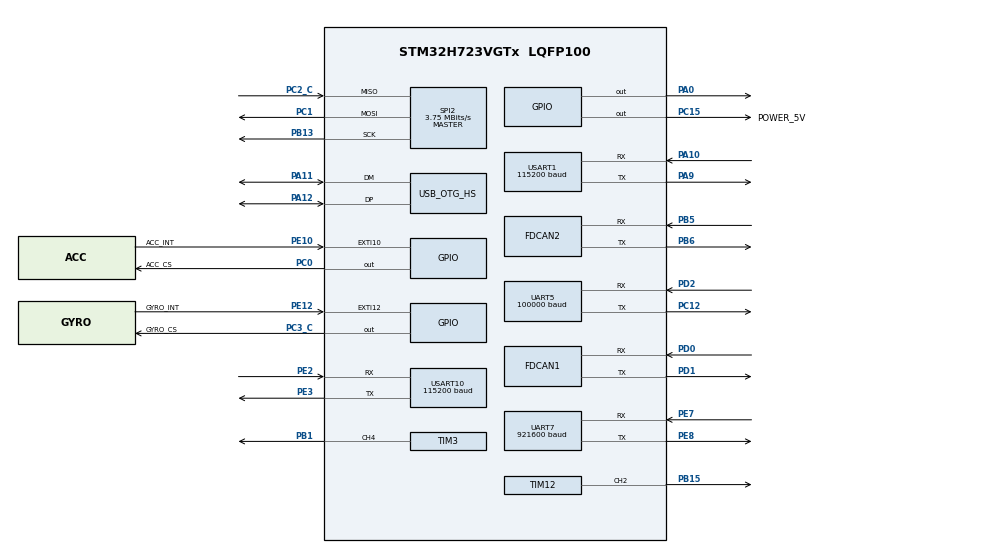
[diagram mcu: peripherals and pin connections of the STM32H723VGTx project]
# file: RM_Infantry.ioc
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CORTEX_M7.BaseAddress-Cortex_Memory_Protection_Unit_Region0_Settings=0x24000000
CORTEX_M7.CPU_DCache=Disabled
CORTEX_M7.CPU_ICache=Enabled
CORTEX_M7.Enable-Cortex_Memory_Protection_Unit_Region0_Settings=MPU_REGION_ENABLE
CORTEX_M7.IsBufferable-Cortex_Memory_Protection_Unit_Region0_Settings=MPU_ACCESS_BUFFERABLE
CORTEX_M7.IsCacheable-Cortex_Memory_Protection_Unit_Region0_Settings=MPU_ACCESS_CACHEABLE
CORTEX_M7.MPU_Control=MPU_HFNMI_PRIVDEF
CORTEX_M7.Size-Cortex_Memory_Protection_Unit_Region0_Settings=MPU_REGION_SIZE_512KB
CORTEX_M7.TypeExtField-Cortex_Memory_Protection_Unit_Region0_Settings=MPU_TEX_LEVEL1
CORTEX_M7.default_mode_Activation=1
Dma.Request0=SPI2_RX
Dma.Request1=SPI2_TX
Dma.Request2=UART5_RX
Dma.Request3=USART1_TX
Dma.Request4=UART7_RX
Dma.Request5=UART7_TX
Dma.Request6=USART10_RX
Dma.Request7=USART10_TX
Dma.Request8=USART1_RX
Dma.SPI2_RX.0.Direction=DMA_PERIPH_TO_MEMORY
Dma.SPI2_RX.0.EventEnable=DISABLE
Dma.SPI2_RX.0.FIFOMode=DMA_FIFOMODE_DISABLE
Dma.SPI2_RX.0.Instance=DMA1_Stream1
Dma.SPI2_RX.0.MemDataAlignment=DMA_MDATAALIGN_BYTE
Dma.SPI2_RX.0.MemInc=DMA_MINC_ENABLE
Dma.SPI2_RX.0.Mode=DMA_NORMAL
Dma.SPI2_RX.0.PeriphDataAlignment=DMA_PDATAALIGN_BYTE
Dma.SPI2_RX.0.PeriphInc=DMA_PINC_DISABLE
Dma.SPI2_RX.0.Polarity=HAL_DMAMUX_REQ_GEN_RISING
Dma.SPI2_RX.0.Priority=DMA_PRIORITY_HIGH
Dma.SPI2_RX.0.RequestNumber=1
Dma.SPI2_RX.0.SignalID=NONE
Dma.SPI2_RX.0.SyncEnable=DISABLE
Dma.SPI2_RX.0.SyncPolarity=HAL_DMAMUX_SYNC_NO_EVENT
Dma.SPI2_RX.0.SyncRequestNumber=1
Dma.SPI2_RX.0.SyncSignalID=NONE
Dma.SPI2_TX.1.Direction=DMA_MEMORY_TO_PERIPH
Dma.SPI2_TX.1.EventEnable=DISABLE
Dma.SPI2_TX.1.FIFOMode=DMA_FIFOMODE_DISABLE
Dma.SPI2_TX.1.Instance=DMA1_Stream2
Dma.SPI2_TX.1.MemDataAlignment=DMA_MDATAALIGN_BYTE
Dma.SPI2_TX.1.MemInc=DMA_MINC_ENABLE
Dma.SPI2_TX.1.Mode=DMA_NORMAL
Dma.SPI2_TX.1.PeriphDataAlignment=DMA_PDATAALIGN_BYTE
Dma.SPI2_TX.1.PeriphInc=DMA_PINC_DISABLE
Dma.SPI2_TX.1.Polarity=HAL_DMAMUX_REQ_GEN_RISING
Dma.SPI2_TX.1.Priority=DMA_PRIORITY_MEDIUM
Dma.SPI2_TX.1.RequestNumber=1
Dma.SPI2_TX.1.SignalID=NONE
Dma.SPI2_TX.1.SyncEnable=DISABLE
Dma.SPI2_TX.1.SyncPolarity=HAL_DMAMUX_SYNC_NO_EVENT
Dma.SPI2_TX.1.SyncRequestNumber=1
Dma.SPI2_TX.1.SyncSignalID=NONE
Dma.UART5_RX.2.Direction=DMA_PERIPH_TO_MEMORY
Dma.UART5_RX.2.EventEnable=DISABLE
Dma.UART5_RX.2.FIFOMode=DMA_FIFOMODE_DISABLE
Dma.UART5_RX.2.Instance=DMA1_Stream3
Dma.UART5_RX.2.MemDataAlignment=DMA_MDATAALIGN_BYTE
Dma.UART5_RX.2.MemInc=DMA_MINC_ENABLE
Dma.UART5_RX.2.Mode=DMA_NORMAL
Dma.UART5_RX.2.PeriphDataAlignment=DMA_PDATAALIGN_BYTE
Dma.UART5_RX.2.PeriphInc=DMA_PINC_DISABLE
Dma.UART5_RX.2.Polarity=HAL_DMAMUX_REQ_GEN_RISING
Dma.UART5_RX.2.Priority=DMA_PRIORITY_LOW
Dma.UART5_RX.2.RequestNumber=1
Dma.UART5_RX.2.SignalID=NONE
Dma.UART5_RX.2.SyncEnable=DISABLE
Dma.UART5_RX.2.SyncPolarity=HAL_DMAMUX_SYNC_NO_EVENT
Dma.UART5_RX.2.SyncRequestNumber=1
Dma.UART5_RX.2.SyncSignalID=NONE
Dma.UART7_RX.4.Direction=DMA_PERIPH_TO_MEMORY
Dma.UART7_RX.4.EventEnable=DISABLE
Dma.UART7_RX.4.FIFOMode=DMA_FIFOMODE_DISABLE
Dma.UART7_RX.4.Instance=DMA2_Stream1
Dma.UART7_RX.4.MemDataAlignment=DMA_MDATAALIGN_BYTE
Dma.UART7_RX.4.MemInc=DMA_MINC_ENABLE
Dma.UART7_RX.4.Mode=DMA_NORMAL
Dma.UART7_RX.4.PeriphDataAlignment=DMA_PDATAALIGN_BYTE
Dma.UART7_RX.4.PeriphInc=DMA_PINC_DISABLE
Dma.UART7_RX.4.Polarity=HAL_DMAMUX_REQ_GEN_RISING
Dma.UART7_RX.4.Priority=DMA_PRIORITY_HIGH
Dma.UART7_RX.4.RequestNumber=1
Dma.UART7_RX.4.SignalID=NONE
Dma.UART7_RX.4.SyncEnable=DISABLE
Dma.UART7_RX.4.SyncPolarity=HAL_DMAMUX_SYNC_NO_EVENT
Dma.UART7_RX.4.SyncRequestNumber=1
Dma.UART7_RX.4.SyncSignalID=NONE
Dma.UART7_TX.5.Direction=DMA_MEMORY_TO_PERIPH
Dma.UART7_TX.5.EventEnable=DISABLE
Dma.UART7_TX.5.FIFOMode=DMA_FIFOMODE_DISABLE
Dma.UART7_TX.5.Instance=DMA2_Stream2
Dma.UART7_TX.5.MemDataAlignment=DMA_MDATAALIGN_BYTE
Dma.UART7_TX.5.MemInc=DMA_MINC_ENABLE
Dma.UART7_TX.5.Mode=DMA_NORMAL
Dma.UART7_TX.5.PeriphDataAlignment=DMA_PDATAALIGN_BYTE
Dma.UART7_TX.5.PeriphInc=DMA_PINC_DISABLE
Dma.UART7_TX.5.Polarity=HAL_DMAMUX_REQ_GEN_RISING
Dma.UART7_TX.5.Priority=DMA_PRIORITY_HIGH
Dma.UART7_TX.5.RequestNumber=1
Dma.UART7_TX.5.SignalID=NONE
Dma.UART7_TX.5.SyncEnable=DISABLE
Dma.UART7_TX.5.SyncPolarity=HAL_DMAMUX_SYNC_NO_EVENT
Dma.UART7_TX.5.SyncRequestNumber=1
Dma.UART7_TX.5.SyncSignalID=NONE
Dma.USART10_RX.6.Direction=DMA_PERIPH_TO_MEMORY
Dma.USART10_RX.6.EventEnable=DISABLE
Dma.USART10_RX.6.FIFOMode=DMA_FIFOMODE_DISABLE
Dma.USART10_RX.6.Instance=DMA2_Stream3
Dma.USART10_RX.6.MemDataAlignment=DMA_MDATAALIGN_BYTE
Dma.USART10_RX.6.MemInc=DMA_MINC_ENABLE
Dma.USART10_RX.6.Mode=DMA_NORMAL
Dma.USART10_RX.6.PeriphDataAlignment=DMA_PDATAALIGN_BYTE
Dma.USART10_RX.6.PeriphInc=DMA_PINC_DISABLE
Dma.USART10_RX.6.Polarity=HAL_DMAMUX_REQ_GEN_RISING
Dma.USART10_RX.6.Priority=DMA_PRIORITY_VERY_HIGH
Dma.USART10_RX.6.RequestNumber=1
Dma.USART10_RX.6.SignalID=NONE
Dma.USART10_RX.6.SyncEnable=DISABLE
Dma.USART10_RX.6.SyncPolarity=HAL_DMAMUX_SYNC_NO_EVENT
Dma.USART10_RX.6.SyncRequestNumber=1
Dma.USART10_RX.6.SyncSignalID=NONE
Dma.USART10_TX.7.Direction=DMA_MEMORY_TO_PERIPH
Dma.USART10_TX.7.EventEnable=DISABLE
Dma.USART10_TX.7.FIFOMode=DMA_FIFOMODE_DISABLE
Dma.USART10_TX.7.Instance=DMA2_Stream4
Dma.USART10_TX.7.MemDataAlignment=DMA_MDATAALIGN_BYTE
Dma.USART10_TX.7.MemInc=DMA_MINC_ENABLE
Dma.USART10_TX.7.Mode=DMA_NORMAL
Dma.USART10_TX.7.PeriphDataAlignment=DMA_PDATAALIGN_BYTE
Dma.USART10_TX.7.PeriphInc=DMA_PINC_DISABLE
Dma.USART10_TX.7.Polarity=HAL_DMAMUX_REQ_GEN_RISING
Dma.USART10_TX.7.Priority=DMA_PRIORITY_HIGH
Dma.USART10_TX.7.RequestNumber=1
Dma.USART10_TX.7.SignalID=NONE
Dma.USART10_TX.7.SyncEnable=DISABLE
Dma.USART10_TX.7.SyncPolarity=HAL_DMAMUX_SYNC_NO_EVENT
Dma.USART10_TX.7.SyncRequestNumber=1
Dma.USART10_TX.7.SyncSignalID=NONE
Dma.USART1_RX.8.Direction=DMA_PERIPH_TO_MEMORY
Dma.USART1_RX.8.EventEnable=DISABLE
Dma.USART1_RX.8.FIFOMode=DMA_FIFOMODE_DISABLE
Dma.USART1_RX.8.Instance=DMA1_Stream0
Dma.USART1_RX.8.MemDataAlignment=DMA_MDATAALIGN_BYTE
Dma.USART1_RX.8.MemInc=DMA_MINC_ENABLE
Dma.USART1_RX.8.Mode=DMA_NORMAL
Dma.USART1_RX.8.PeriphDataAlignment=DMA_PDATAALIGN_BYTE
Dma.USART1_RX.8.PeriphInc=DMA_PINC_DISABLE
Dma.USART1_RX.8.Polarity=HAL_DMAMUX_REQ_GEN_RISING
Dma.USART1_RX.8.Priority=DMA_PRIORITY_LOW
Dma.USART1_RX.8.RequestNumber=1
Dma.USART1_RX.8.SignalID=NONE
Dma.USART1_RX.8.SyncEnable=DISABLE
Dma.USART1_RX.8.SyncPolarity=HAL_DMAMUX_SYNC_NO_EVENT
Dma.USART1_RX.8.SyncRequestNumber=1
Dma.USART1_RX.8.SyncSignalID=NONE
Dma.USART1_TX.3.Direction=DMA_MEMORY_TO_PERIPH
Dma.USART1_TX.3.EventEnable=DISABLE
Dma.USART1_TX.3.FIFOMode=DMA_FIFOMODE_DISABLE
Dma.USART1_TX.3.Instance=DMA2_Stream0
Dma.USART1_TX.3.MemDataAlignment=DMA_MDATAALIGN_BYTE
Dma.USART1_TX.3.MemInc=DMA_MINC_ENABLE
Dma.USART1_TX.3.Mode=DMA_NORMAL
Dma.USART1_TX.3.PeriphDataAlignment=DMA_PDATAALIGN_BYTE
Dma.USART1_TX.3.PeriphInc=DMA_PINC_DISABLE
Dma.USART1_TX.3.Polarity=HAL_DMAMUX_REQ_GEN_RISING
Dma.USART1_TX.3.Priority=DMA_PRIORITY_LOW
Dma.USART1_TX.3.RequestNumber=1
Dma.USART1_TX.3.SignalID=NONE
Dma.USART1_TX.3.SyncEnable=DISABLE
Dma.USART1_TX.3.SyncPolarity=HAL_DMAMUX_SYNC_NO_EVENT
Dma.USART1_TX.3.SyncRequestNumber=1
Dma.USART1_TX.3.SyncSignalID=NONE
FDCAN1.CalculateBaudRateNominal=1000000
FDCAN1.CalculateTimeBitNominal=1000
FDCAN1.CalculateTimeQuantumNominal=25.0
FDCAN1.DataPrescaler=3
FDCAN1.DataSyncJumpWidth=10
FDCAN1.DataTimeSeg1=29
FDCAN1.DataTimeSeg2=10
FDCAN1.NominalPrescaler=3
FDCAN1.NominalSyncJumpWidth=10
FDCAN1.NominalTimeSeg1=29
FDCAN1.NominalTimeSeg2=10
FDCAN1.ProtocolException=ENABLE
FDCAN1.RxFifo0ElmtsNbr=2
FDCAN1.StdFiltersNbr=1
FDCAN1.TxFifoQueueElmtsNbr=2
FDCAN2.CalculateBaudRateNominal=1000000
FDCAN2.CalculateTimeBitNominal=1000
FDCAN2.CalculateTimeQuantumNominal=25.0
FDCAN2.DataPrescaler=3
FDCAN2.DataSyncJumpWidth=10
FDCAN2.DataTimeSeg1=29
FDCAN2.DataTimeSeg2=10
FDCAN2.MessageRAMOffset=1280
FDCAN2.NominalPrescaler=3
FDCAN2.NominalSyncJumpWidth=10
FDCAN2.NominalTimeSeg1=29
FDCAN2.NominalTimeSeg2=10
FDCAN2.ProtocolException=ENABLE
FDCAN2.RxFifo0ElmtsNbr=2
FDCAN2.StdFiltersNbr=1
FDCAN2.TxFifoQueueElmtsNbr=2
FREERTOS.BinarySemaphores01=imuBinarySem01,Static,imuBinarySemControlBlock
FREERTOS.Tasks01=defaultTask,24,128,StartDefaultTask,Default,NULL,Dynamic,NULL,NULL;Trans_Task,24,512,Trans_Task_main,As weak,NULL,Dynamic,NULL,NULL;Chassic_Task,8,512,Chassis_Task_main,As weak,NULL,Dynamic,NULL,NULL;imuTempCtrl,32,256,IMU_Task,As weak,NULL,Dynamic,NULL,NULL
Mcu.Family=STM32H7
Mcu.Name=STM32H723VGTx
Mcu.Package=LQFP100
NVIC.DMA1_Stream0_IRQn=true\:5\:0\:false\:false\:true\:true\:false\:true\:true
NVIC.DMA1_Stream1_IRQn=true\:5\:0\:false\:false\:true\:true\:false\:true\:true
NVIC.DMA1_Stream2_IRQn=true\:5\:0\:false\:false\:true\:true\:false\:true\:true
NVIC.DMA1_Stream3_IRQn=true\:5\:0\:false\:false\:true\:true\:false\:true\:true
NVIC.DMA2_Stream0_IRQn=true\:5\:0\:false\:false\:true\:true\:false\:true\:true
NVIC.DMA2_Stream1_IRQn=true\:5\:0\:false\:false\:true\:false\:false\:true\:true
NVIC.DMA2_Stream2_IRQn=true\:5\:0\:false\:false\:true\:false\:false\:true\:true
NVIC.DMA2_Stream3_IRQn=true\:5\:0\:false\:false\:true\:false\:false\:true\:true
NVIC.DMA2_Stream4_IRQn=true\:5\:0\:false\:false\:true\:false\:false\:true\:true
NVIC.FDCAN1_IT0_IRQn=true\:5\:0\:false\:false\:true\:true\:true\:true\:true
NVIC.FDCAN1_IT1_IRQn=true\:5\:0\:false\:false\:true\:true\:true\:true\:true
NVIC.FDCAN2_IT0_IRQn=true\:5\:0\:false\:false\:true\:true\:true\:true\:true
NVIC.FDCAN2_IT1_IRQn=true\:5\:0\:false\:false\:true\:true\:true\:true\:true
NVIC.OTG_HS_IRQn=true\:5\:0\:false\:false\:true\:true\:true\:true\:true
NVIC.PriorityGroup=NVIC_PRIORITYGROUP_4
NVIC.SPI2_IRQn=true\:5\:0\:false\:false\:true\:true\:true\:true\:true
NVIC.TIM6_DAC_IRQn=true\:5\:0\:false\:false\:true\:true\:true\:true\:true
NVIC.TIM7_IRQn=true\:15\:0\:false\:false\:true\:false\:false\:true\:true
NVIC.TimeBase=TIM7_IRQn
NVIC.TimeBaseIP=TIM7
NVIC.UART5_IRQn=true\:5\:0\:false\:false\:true\:true\:true\:true\:true
NVIC.UART7_IRQn=true\:5\:0\:false\:false\:true\:true\:true\:true\:true
NVIC.USART10_IRQn=true\:5\:0\:false\:false\:true\:true\:true\:true\:true
NVIC.USART1_IRQn=true\:5\:0\:false\:false\:true\:true\:true\:true\:true
PA0.GPIO_Speed=GPIO_SPEED_FREQ_VERY_HIGH
PA0.Signal=GPIO_Output
PA10.Mode=Asynchronous
PA10.Signal=USART1_RX
PA11.Mode=Device_Only_FS
PA11.Signal=USB_OTG_HS_DM
PA12.Mode=Device_Only_FS
PA12.Signal=USB_OTG_HS_DP
PA13(JTMS/SWDIO).Mode=Serial_Wire
PA13(JTMS/SWDIO).Signal=DEBUG_JTMS-SWDIO
PA14(JTCK/SWCLK).Mode=Serial_Wire
PA14(JTCK/SWCLK).Signal=DEBUG_JTCK-SWCLK
PA9.Mode=Asynchronous
PA9.Signal=USART1_TX
PB1.Signal=S_TIM3_CH4
PB13.GPIO_Speed=GPIO_SPEED_FREQ_VERY_HIGH
PB13.Mode=Full_Duplex_Master
PB13.Signal=SPI2_SCK
PB15.Signal=S_TIM12_CH2
PB5.Mode=FDCAN_Activate
PB5.Signal=FDCAN2_RX
PB6.Mode=FDCAN_Activate
PB6.Signal=FDCAN2_TX
PC0.GPIO_Label=ACC_CS
PC0.GPIO_Speed=GPIO_SPEED_FREQ_VERY_HIGH
PC0.PinState=GPIO_PIN_SET
PC0.Signal=GPIO_Output
PC1.GPIO_Speed=GPIO_SPEED_FREQ_VERY_HIGH
PC1.Mode=Full_Duplex_Master
PC1.Signal=SPI2_MOSI
PC12.Mode=Asynchronous
PC12.Signal=UART5_TX
PC15-OSC32_OUT.GPIO_Label=POWER_5V
PC15-OSC32_OUT.PinState=GPIO_PIN_SET
PC15-OSC32_OUT.Signal=GPIO_Output
PC2_C.GPIO_Speed=GPIO_SPEED_FREQ_VERY_HIGH
PC2_C.Mode=Full_Duplex_Master
PC2_C.Signal=SPI2_MISO
PC3_C.GPIO_Label=GYRO_CS
PC3_C.GPIO_Speed=GPIO_SPEED_FREQ_VERY_HIGH
PC3_C.PinState=GPIO_PIN_SET
PC3_C.Signal=GPIO_Output
PD0.Mode=FDCAN_Activate
PD0.Signal=FDCAN1_RX
PD1.Mode=FDCAN_Activate
PD1.Signal=FDCAN1_TX
PD2.GPIO_PuPd=GPIO_PULLUP
PD2.GPIO_Speed=GPIO_SPEED_FREQ_HIGH
PD2.Mode=Asynchronous
PD2.Signal=UART5_RX
PE10.GPIO_Label=ACC_INT
PE10.Signal=GPXTI10
PE12.GPIO_Label=GYRO_INT
PE12.Signal=GPXTI12
PE2.Mode=Asynchronous
PE2.Signal=USART10_RX
PE3.Mode=Asynchronous
PE3.Signal=USART10_TX
PE7.GPIO_PuPd=GPIO_PULLUP
PE7.GPIO_Speed=GPIO_SPEED_FREQ_VERY_HIGH
PE7.Mode=Asynchronous
PE7.Signal=UART7_RX
PE8.Mode=Asynchronous
PE8.Signal=UART7_TX
PH0-OSC_IN.Mode=HSE-External-Oscillator
PH0-OSC_IN.Signal=RCC_OSC_IN
PH1-OSC_OUT.Mode=HSE-External-Oscillator
PH1-OSC_OUT.Signal=RCC_OSC_OUT
ProjectManager.HeapSize=0x200
ProjectManager.StackSize=0x400
ProjectManager.TargetToolchain=Makefile
RCC.ADCFreq_Value=60000000
RCC.APB1Freq_Value=120000000
RCC.APB2Freq_Value=120000000
RCC.APB3Freq_Value=120000000
RCC.APB4Freq_Value=120000000
RCC.CortexFreq_Value=480000000
RCC.D1PPRE=RCC_APB3_DIV2
RCC.D2PPRE1=RCC_APB1_DIV2
RCC.D2PPRE2=RCC_APB2_DIV2
RCC.D3PPRE=RCC_APB4_DIV2
RCC.DIVM1=4
RCC.DIVM2=24
RCC.DIVN1=80
RCC.DIVN2=120
RCC.DIVP1=1
RCC.DIVQ1=4
RCC.DIVQ2=1
RCC.HCLKFreq_Value=240000000
RCC.HPRE=RCC_HCLK_DIV2
RCC.HSE_VALUE=24000000
RCC.PLL2FRACN=0
RCC.PLL3FRACN=0
RCC.PLLFRACN=0
RCC.PLLSourceVirtual=RCC_PLLSOURCE_HSE
RCC.PWR_Regulator_Voltage_Scale=PWR_REGULATOR_VOLTAGE_SCALE0
RCC.SYSCLKFreq_VALUE=480000000
RCC.SYSCLKSource=RCC_SYSCLKSOURCE_PLLCLK
RCC.USBCLockSelection=RCC_USBCLKSOURCE_HSI48
RCC.USBFreq_Value=48000000
SH.S_TIM12_CH2.0=TIM12_CH2,PWM Generation2 CH2
SH.S_TIM3_CH4.0=TIM3_CH4,PWM Generation4 CH4
SPI2.BaudRatePrescaler=SPI_BAUDRATEPRESCALER_32
SPI2.CLKPhase=SPI_PHASE_2EDGE
SPI2.CLKPolarity=SPI_POLARITY_HIGH
SPI2.CalculateBaudRate=3.75 MBits/s
SPI2.DataSize=SPI_DATASIZE_8BIT
SPI2.Direction=SPI_DIRECTION_2LINES
SPI2.Mode=SPI_MODE_MASTER
SPI2.VirtualType=VM_MASTER
TIM12.Channel-PWM\ Generation2\ CH2=TIM_CHANNEL_2
TIM12.Period=1000
TIM12.Prescaler=24000-1
TIM12.Pulse-PWM\ Generation2\ CH2=12
TIM3.AutoReloadPreload=TIM_AUTORELOAD_PRELOAD_ENABLE
TIM3.Channel-PWM\ Generation4\ CH4=TIM_CHANNEL_4
TIM3.Period=10000-1
TIM3.Prescaler=24-1
TIM6.Period=10000-1
TIM6.Prescaler=24000-1
UART5.BaudRate=100000
UART5.Parity=PARITY_EVEN
UART5.StopBits=UART_STOPBITS_2
UART5.WordLength=WORDLENGTH_9B
UART7.BaudRate=921600
USART1.BaudRate=115200
USART1.VirtualMode-Asynchronous=VM_ASYNC
USART10.BaudRate=115200
USART10.DMADisableonRxErrorParam=ADVFEATURE_DMA_ENABLEONRXERROR
USART10.VirtualMode=VM_ASYNC
USB_DEVICE.CLASS_NAME_HS=CDC
USB_DEVICE.VirtualMode=Cdc
USB_DEVICE.VirtualModeHS=Cdc_HS
USB_OTG_HS.VirtualMode-Device_Only_FS=Device_Only_FS
VP_FREERTOS_VS_CMSIS_V2.Mode=CMSIS_V2
VP_MEMORYMAP_VS_MEMORYMAP.Mode=CurAppReg
VP_SYS_VS_tim7.Mode=TIM7
VP_TIM6_VS_ClockSourceINT.Mode=Enable_Timer
VP_USB_DEVICE_VS_USB_DEVICE_CDC_HS.Mode=CDC_HS
board=custom

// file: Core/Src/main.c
/* USER CODE BEGIN Header */
/**
  ******************************************************************************
  * @file           : main.c
  * @brief          : Main program body
  ******************************************************************************
  * @attention
  *
  * Copyright (c) 2026 STMicroelectronics.
  * All rights reserved.
  *
  * This software is licensed under terms that can be found in the LICENSE file
  * in the root directory of this software component.
  * If no LICENSE file comes with this software, it is provided AS-IS.
  *
  ******************************************************************************
  */
/* USER CODE END Header */
#include "main.h"
#include "cmsis_os.h"
#include "dma.h"
#include "fdcan.h"
#include "memorymap.h"
#include "spi.h"
#include "tim.h"
#include "usart.h"
#include "usb_device.h"
#include "gpio.h"

/* USER CODE BEGIN Includes */
#include "bsp_fdcan.h"
#include "dm_motor_ctrl.h"
/* USER CODE END Includes */

void SystemClock_Config(void);
static void MPU_Config(void);
void MX_FREERTOS_Init(void);

int main(void)
{

  /* MPU Configuration--------------------------------------------------------*/
  MPU_Config();

  /* Enable the CPU Cache */

  /* Enable I-Cache---------------------------------------------------------*/
  SCB_EnableICache();

  /* MCU Configuration--------------------------------------------------------*/

  /* Reset of all peripherals, Initializes the Flash interface and the Systick. */
  HAL_Init();

  /* Configure the system clock */
  SystemClock_Config();

  /* Initialize all configured peripherals */
  MX_GPIO_Init();
  MX_DMA_Init();
  MX_FDCAN2_Init();
  MX_USART1_UART_Init();
  MX_TIM6_Init();
  MX_FDCAN1_Init();
  MX_UART5_Init();
  MX_TIM12_Init();
  MX_SPI2_Init();
  MX_TIM3_Init();
  MX_UART7_Init();
  MX_USART10_UART_Init();

  /* Init scheduler */
  osKernelInitialize();

  /* Call init function for freertos objects (in cmsis_os2.c) */
  MX_FREERTOS_Init();

  /* Start scheduler */
  osKernelStart();

  /* We should never get here as control is now taken by the scheduler */

  /* Infinite loop */
  while (1)
  {

  }
}

void SystemClock_Config(void)
{
  RCC_OscInitTypeDef RCC_OscInitStruct = {0};
  RCC_ClkInitTypeDef RCC_ClkInitStruct = {0};

  /** Supply configuration update enable
  */
  HAL_PWREx_ConfigSupply(PWR_LDO_SUPPLY);

  /** Configure the main internal regulator output voltage
  */
  __HAL_PWR_VOLTAGESCALING_CONFIG(PWR_REGULATOR_VOLTAGE_SCALE0);

  while(!__HAL_PWR_GET_FLAG(PWR_FLAG_VOSRDY)) {}

  /** Initializes the RCC Oscillators according to the specified parameters
  * in the RCC_OscInitTypeDef structure.
  */
  RCC_OscInitStruct.OscillatorType = RCC_OSCILLATORTYPE_HSI48|RCC_OSCILLATORTYPE_HSE;
  RCC_OscInitStruct.HSEState = RCC_HSE_ON;
  RCC_OscInitStruct.HSI48State = RCC_HSI48_ON;
  RCC_OscInitStruct.PLL.PLLState = RCC_PLL_ON;
  RCC_OscInitStruct.PLL.PLLSource = RCC_PLLSOURCE_HSE;
  RCC_OscInitStruct.PLL.PLLM = 4;
  RCC_OscInitStruct.PLL.PLLN = 80;
  RCC_OscInitStruct.PLL.PLLP = 1;
  RCC_OscInitStruct.PLL.PLLQ = 4;
  RCC_OscInitStruct.PLL.PLLR = 2;
  RCC_OscInitStruct.PLL.PLLRGE = RCC_PLL1VCIRANGE_2;
  RCC_OscInitStruct.PLL.PLLVCOSEL = RCC_PLL1VCOWIDE;
  RCC_OscInitStruct.PLL.PLLFRACN = 0;
  if (HAL_RCC_OscConfig(&RCC_OscInitStruct) != HAL_OK)
  {
    Error_Handler();
  }

  /** Initializes the CPU, AHB and APB buses clocks
  */
  RCC_ClkInitStruct.ClockType = RCC_CLOCKTYPE_HCLK|RCC_CLOCKTYPE_SYSCLK
                              |RCC_CLOCKTYPE_PCLK1|RCC_CLOCKTYPE_PCLK2
                              |RCC_CLOCKTYPE_D3PCLK1|RCC_CLOCKTYPE_D1PCLK1;
  RCC_ClkInitStruct.SYSCLKSource = RCC_SYSCLKSOURCE_PLLCLK;
  RCC_ClkInitStruct.SYSCLKDivider = RCC_SYSCLK_DIV1;
  RCC_ClkInitStruct.AHBCLKDivider = RCC_HCLK_DIV2;
  RCC_ClkInitStruct.APB3CLKDivider = RCC_APB3_DIV2;
  RCC_ClkInitStruct.APB1CLKDivider = RCC_APB1_DIV2;
  RCC_ClkInitStruct.APB2CLKDivider = RCC_APB2_DIV2;
  RCC_ClkInitStruct.APB4CLKDivider = RCC_APB4_DIV2;

  if (HAL_RCC_ClockConfig(&RCC_ClkInitStruct, FLASH_LATENCY_3) != HAL_OK)
  {
    Error_Handler();
  }
}

 /* MPU Configuration */

void MPU_Config(void)
{
  MPU_Region_InitTypeDef MPU_InitStruct = {0};

  /* Disables the MPU */
  HAL_MPU_Disable();

  /** Initializes and configures the Region and the memory to be protected
  */
  MPU_InitStruct.Enable = MPU_REGION_ENABLE;
  MPU_InitStruct.Number = MPU_REGION_NUMBER0;
  MPU_InitStruct.BaseAddress = 0x0;
  MPU_InitStruct.Size = MPU_REGION_SIZE_4GB;
  MPU_InitStruct.SubRegionDisable = 0x87;
  MPU_InitStruct.TypeExtField = MPU_TEX_LEVEL0;
  MPU_InitStruct.AccessPermission = MPU_REGION_NO_ACCESS;
  MPU_InitStruct.DisableExec = MPU_INSTRUCTION_ACCESS_DISABLE;
  MPU_InitStruct.IsShareable = MPU_ACCESS_SHAREABLE;
  MPU_InitStruct.IsCacheable = MPU_ACCESS_NOT_CACHEABLE;
  MPU_InitStruct.IsBufferable = MPU_ACCESS_NOT_BUFFERABLE;

  HAL_MPU_ConfigRegion(&MPU_InitStruct);
  /* Enables the MPU */
  HAL_MPU_Enable(MPU_HFNMI_PRIVDEF);

}

void HAL_TIM_PeriodElapsedCallback(TIM_HandleTypeDef *htim)
{
  if (htim->Instance == TIM7)
  {
    HAL_IncTick();
  }
}

void Error_Handler(void)
{
  __disable_irq();
  while (1)
  {
  }
}

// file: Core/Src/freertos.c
/* USER CODE BEGIN Header */
/**
  ******************************************************************************
  * File Name          : freertos.c
  * Description        : Code for freertos applications
  ******************************************************************************
  * @attention
  *
  * Copyright (c) 2026 STMicroelectronics.
  * All rights reserved.
  *
  * This software is licensed under terms that can be found in the LICENSE file
  * in the root directory of this software component.
  * If no LICENSE file comes with this software, it is provided AS-IS.
  *
  ******************************************************************************
  */
/* USER CODE END Header */

#include "FreeRTOS.h"
#include "task.h"
#include "main.h"
#include "cmsis_os.h"

/* Definitions for defaultTask */
osThreadId_t defaultTaskHandle;
const osThreadAttr_t defaultTask_attributes = {
  .name = "defaultTask",
  .stack_size = 128 * 4,
  .priority = (osPriority_t) osPriorityNormal,
};
/* Definitions for Trans_Task */
osThreadId_t Trans_TaskHandle;
const osThreadAttr_t Trans_Task_attributes = {
  .name = "Trans_Task",
  .stack_size = 512 * 4,
  .priority = (osPriority_t) osPriorityNormal,
};
/* Definitions for Chassic_Task */
osThreadId_t Chassic_TaskHandle;
const osThreadAttr_t Chassic_Task_attributes = {
  .name = "Chassic_Task",
  .stack_size = 512 * 4,
  .priority = (osPriority_t) osPriorityLow,
};
/* Definitions for imuTempCtrl */
osThreadId_t imuTempCtrlHandle;
const osThreadAttr_t imuTempCtrl_attributes = {
  .name = "imuTempCtrl",
  .stack_size = 256 * 4,
  .priority = (osPriority_t) osPriorityAboveNormal,
};
/* Definitions for imuBinarySem01 */
osSemaphoreId_t imuBinarySem01Handle;
const osSemaphoreAttr_t imuBinarySem01_attributes = {
  .name = "imuBinarySem01"
};

void StartDefaultTask(void *argument);
void Trans_Task_main(void *argument);
void Chassis_Task_main(void *argument);
void IMU_Task(void *argument);

extern void MX_USB_DEVICE_Init(void);
void MX_FREERTOS_Init(void); /* (MISRA C 2004 rule 8.1) */

void MX_FREERTOS_Init(void) {

  /* Create the semaphores(s) */
  /* creation of imuBinarySem01 */
  imuBinarySem01Handle = osSemaphoreNew(1, 0, &imuBinarySem01_attributes);

  /* Create the thread(s) */
  /* creation of defaultTask */
  defaultTaskHandle = osThreadNew(StartDefaultTask, NULL, &defaultTask_attributes);

  /* creation of Trans_Task */
  Trans_TaskHandle = osThreadNew(Trans_Task_main, NULL, &Trans_Task_attributes);

  /* creation of Chassic_Task */
  Chassic_TaskHandle = osThreadNew(Chassis_Task_main, NULL, &Chassic_Task_attributes);

  /* creation of imuTempCtrl */
  imuTempCtrlHandle = osThreadNew(IMU_Task, NULL, &imuTempCtrl_attributes);

}

void StartDefaultTask(void *argument)
{
  /* init code for USB_DEVICE */
  MX_USB_DEVICE_Init();
  for(;;)
  {
    osDelay(1);
  }
}

__weak void Trans_Task_main(void *argument)
{
  for(;;)
  {
    osDelay(1);
  }
}

__weak void Chassis_Task_main(void *argument)
{
  for(;;)
  {
    osDelay(1);
  }
}

__weak void IMU_Task(void *argument)
{
  for(;;)
  {
    osDelay(1);
  }
}
